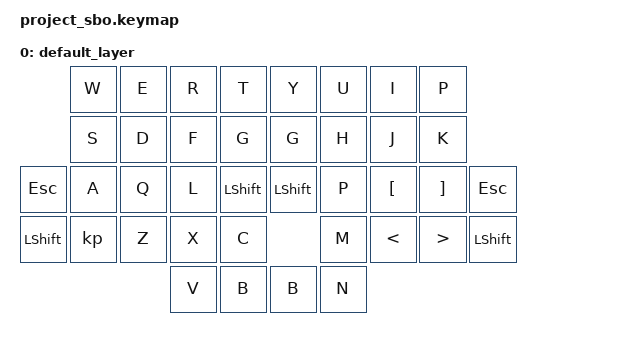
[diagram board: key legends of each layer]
/*
 * Copyright (c) 2022 The ZMK Contributors
 *
 * SPDX-License-Identifier: MIT
 */

#include <behaviors.dtsi>
#include <dt-bindings/zmk/keys.h>

#define DEF_L 0
//               |     W     |     E     |     R     |     T     |     Y     |     U     |     I     |     P     |  
//               |     S     |     D     |     F     |     G     |     G     |     H     |     J     |     K     |
//    |    ESC   |     A     |     Q     |     L     |   SHIFT   |   SHIFT   |     P     |     [     |     ]     |    ESC    |
//    |   SHIFT  |     Z     |     X     |     C     |                       |     M     |     <     |     >     |   SHIFT   |
//                                       |     V     |     B     |     B     |     N     |



/ {
    keymap {
        compatible = "zmk,keymap";

        default_layer {
            bindings = <
                     &kp W       &kp E       &kp R       &kp T       &kp Y       &kp U       &kp I       &kp P
                     &kp S       &kp D       &kp F       &kp G       &kp G       &kp H       &kp J       &kp K
          &kp ESC    &kp A       &kp Q       &kp L     &kp LSHIFT &kp LSHIFT     &kp P      &kp LBKT   &kp RBKT     &kp ESC
       &kp LSHIFT    $kp Z       &kp X       &kp C                               &kp M      &kp LT     &kp GT      &kp LSHIFT
                                             &kp V       &kp B       &kp B       &kp N
                            >;
        };
    };
};
